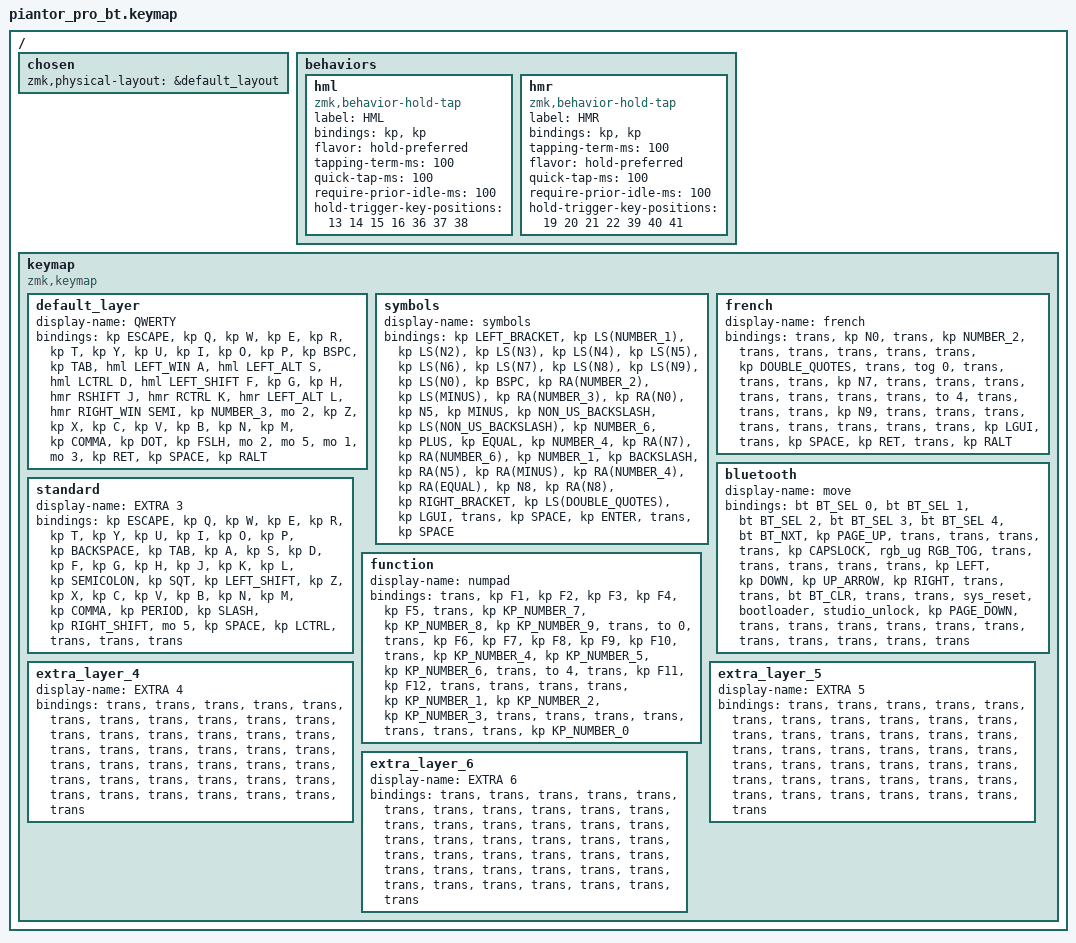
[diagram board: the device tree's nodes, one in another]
/*
 * Copyright (c) 2020 The ZMK Contributors
 *
 * SPDX-License-Identifier: MIT
 */

#include <behaviors.dtsi>
#include <dt-bindings/zmk/bt.h>
#include <dt-bindings/zmk/keys.h>
#include <dt-bindings/zmk/rgb.h>

/ {
    chosen { zmk,physical-layout = &default_layout; };
};

/ {
    behaviors {
        hml: hml {
            compatible = "zmk,behavior-hold-tap";
            label = "HML";
            bindings = <&kp>, <&kp>;

            #binding-cells = <2>;
            flavor = "hold-preferred";
            tapping-term-ms = <100>;
            quick-tap-ms = <100>;
            require-prior-idle-ms = <100>;
            hold-trigger-key-positions = <13 14 15 16 36 37 38>;
        };

        hmr: hmr {
            compatible = "zmk,behavior-hold-tap";
            label = "HMR";
            bindings = <&kp>, <&kp>;

            #binding-cells = <2>;
            tapping-term-ms = <100>;
            flavor = "hold-preferred";
            quick-tap-ms = <100>;
            require-prior-idle-ms = <100>;
            hold-trigger-key-positions = <19 20 21 22 39 40 41>;
        };
    };

    keymap {
        compatible = "zmk,keymap";

        default_layer {
            display-name = "QWERTY";

            // --------------------------------------------------------------------------------
            // |  TAB |  Q  |  W  |  E  |  R  |  T  |  Y  |  U   |  I  |  O  |  P  | BSPC |
            // | CTRL |  A  |  S  |  D  |  F  |  G  |  H  |  J   |  K  |  L  |  ;  |  '   |
            // | SHFT |  Z  |  X  |  C  |  V  |  B  |  N  |  M   |  ,  |  .  |  /  | ESC  |
            //                    | GUI | LWR | SPC | ENT | RSE  | ALT |

            bindings = <
&kp ESCAPE  &kp Q  &kp W  &kp E  &kp R  &kp T  &kp Y  &kp U  &kp I  &kp O  &kp P  &kp BSPC  &kp TAB  &hml LEFT_WIN A  &hml LEFT_ALT S  &hml LCTRL D  &hml LEFT_SHIFT F  &kp G  &kp H  &hmr RSHIFT J  &hmr RCTRL K  &hmr LEFT_ALT L  &hmr RIGHT_WIN SEMI  &kp NUMBER_3  &mo 2  &kp Z  &kp X  &kp C  &kp V  &kp B  &kp N  &kp M  &kp COMMA  &kp DOT  &kp FSLH  &mo 2  &mo 5  &mo 1  &mo 3  &kp RET  &kp SPACE  &kp RALT
            >;
        };

        symbols {
            display-name = "symbols";

            // -----------------------------------------------------------------------------------------
            // |  TAB |  1  |  2  |  3  |  4  |  5    |  6  |  7  |  8  |  9  |  0  | BSPC |
            // | CTRL | BT1 | BT2 | BT3 | BT4 | BT5   | LFT | DWN |  UP | RGT |     |      |
            // | SHFT | BTCR| RGB | RST | BOOT| Unlock|     |     |     |     |     |      |
            //                    | GUI |     | SPC   | ENT |     | ALT |

            bindings = <
&kp LEFT_BRACKET  &kp LS(NUMBER_1)  &kp LS(N2)  &kp LS(N3)  &kp LS(N4)  &kp LS(N5)  &kp LS(N6)  &kp LS(N7)  &kp LS(N8)  &kp LS(N9)  &kp LS(N0)  &kp BSPC  &kp RA(NUMBER_2)  &kp LS(MINUS)  &kp RA(NUMBER_3)  &kp RA(N0)  &kp N5  &kp MINUS  &kp NON_US_BACKSLASH  &kp LS(NON_US_BACKSLASH)  &kp NUMBER_6  &kp PLUS  &kp EQUAL  &kp NUMBER_4  &kp RA(N7)  &kp RA(NUMBER_6)  &kp NUMBER_1  &kp BACKSLASH  &kp RA(N5)  &kp RA(MINUS)  &kp RA(NUMBER_4)  &kp RA(EQUAL)  &kp N8  &kp RA(N8)  &kp RIGHT_BRACKET  &kp LS(DOUBLE_QUOTES)  &kp LGUI  &trans  &kp SPACE  &kp ENTER  &trans  &kp SPACE
            >;
        };

        french {
            display-name = "french";

            // -----------------------------------------------------------------------------------------
            // |  TAB |  !  |  @  |  #  |  $  |  %  |  ^  |  &  |  *  |  (  |  )  | BSPC |
            // | CTRL | HUD | HUI |     |     |     |  -  |  =  |  [  |  ]  |  \  |  `   |
            // | SHFT |     |     |     |     |     |  _  |  +  |  {  |  }  | "|" |  ~   |
            //                    | GUI |     | SPC | ENT |     | ALT |

            bindings = <
&trans  &kp N0  &trans  &kp NUMBER_2  &trans  &trans  &trans  &trans  &trans  &kp DOUBLE_QUOTES  &trans  &tog 0  &trans  &trans  &trans  &kp N7  &trans  &trans  &trans  &trans  &trans  &trans  &trans  &to 4  &trans  &trans  &trans  &kp N9  &trans  &trans  &trans  &trans  &trans  &trans  &trans  &trans  &kp LGUI  &trans  &kp SPACE  &kp RET  &trans  &kp RALT
            >;
        };

        bluetooth {
            display-name = "move";
            bindings = <
&bt BT_SEL 0  &bt BT_SEL 1  &bt BT_SEL 2  &bt BT_SEL 3  &bt BT_SEL 4  &bt BT_NXT  &kp PAGE_UP  &trans  &trans  &trans  &trans  &kp CAPSLOCK  &rgb_ug RGB_TOG  &trans  &trans  &trans  &trans  &trans  &kp LEFT  &kp DOWN  &kp UP_ARROW  &kp RIGHT  &trans  &trans  &bt BT_CLR  &trans  &trans  &sys_reset  &bootloader  &studio_unlock  &kp PAGE_DOWN  &trans  &trans  &trans  &trans  &trans  &trans  &trans  &trans  &trans  &trans  &trans
            >;
        };

        standard {
            display-name = "EXTRA 3";
            bindings = <
&kp ESCAPE  &kp Q  &kp W  &kp E  &kp R  &kp T  &kp Y  &kp U  &kp I  &kp O  &kp P  &kp BACKSPACE  &kp TAB  &kp A  &kp S  &kp D  &kp F  &kp G  &kp H  &kp J  &kp K  &kp L  &kp SEMICOLON  &kp SQT  &kp LEFT_SHIFT  &kp Z  &kp X  &kp C  &kp V  &kp B  &kp N  &kp M  &kp COMMA  &kp PERIOD  &kp SLASH  &kp RIGHT_SHIFT  &mo 5  &kp SPACE  &kp LCTRL  &trans  &trans  &trans
            >;
        };

        function {
            display-name = "numpad";
            bindings = <
&trans  &kp F1  &kp F2  &kp F3  &kp F4  &kp F5  &trans  &kp KP_NUMBER_7  &kp KP_NUMBER_8  &kp KP_NUMBER_9  &trans  &to 0  &trans  &kp F6  &kp F7  &kp F8  &kp F9  &kp F10  &trans  &kp KP_NUMBER_4  &kp KP_NUMBER_5  &kp KP_NUMBER_6  &trans  &to 4  &trans  &kp F11  &kp F12  &trans  &trans  &trans  &trans  &kp KP_NUMBER_1  &kp KP_NUMBER_2  &kp KP_NUMBER_3  &trans  &trans  &trans  &trans  &trans  &trans  &trans  &kp KP_NUMBER_0
            >;
        };

        extra_layer_4 {
            display-name = "EXTRA 4";
            bindings = <
&trans  &trans  &trans  &trans  &trans  &trans  &trans  &trans  &trans  &trans  &trans  &trans  &trans  &trans  &trans  &trans  &trans  &trans  &trans  &trans  &trans  &trans  &trans  &trans  &trans  &trans  &trans  &trans  &trans  &trans  &trans  &trans  &trans  &trans  &trans  &trans  &trans  &trans  &trans  &trans  &trans  &trans
            >;
        };

        extra_layer_5 {
            display-name = "EXTRA 5";
            bindings = <
&trans  &trans  &trans  &trans  &trans  &trans  &trans  &trans  &trans  &trans  &trans  &trans  &trans  &trans  &trans  &trans  &trans  &trans  &trans  &trans  &trans  &trans  &trans  &trans  &trans  &trans  &trans  &trans  &trans  &trans  &trans  &trans  &trans  &trans  &trans  &trans  &trans  &trans  &trans  &trans  &trans  &trans
            >;
        };

        extra_layer_6 {
            display-name = "EXTRA 6";
            bindings = <
&trans  &trans  &trans  &trans  &trans  &trans  &trans  &trans  &trans  &trans  &trans  &trans  &trans  &trans  &trans  &trans  &trans  &trans  &trans  &trans  &trans  &trans  &trans  &trans  &trans  &trans  &trans  &trans  &trans  &trans  &trans  &trans  &trans  &trans  &trans  &trans  &trans  &trans  &trans  &trans  &trans  &trans
            >;
        };
    };
};
